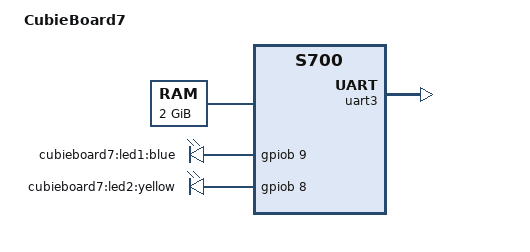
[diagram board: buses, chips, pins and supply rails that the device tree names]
/*
 * Copyright (c) 2017 Andreas Färber
 *
 * SPDX-License-Identifier: (GPL-2.0+ OR MIT)
 */

/dts-v1/;

#include <dt-bindings/gpio/gpio.h>

#include "s700.dtsi"

/ {
	compatible = "cubietech,cubieboard7", "actions,s700";
	model = "CubieBoard7";

	aliases {
		serial3 = &uart3;
	};

	chosen {
		stdout-path = "serial3:115200n8";
	};

	memory@0 {
		device_type = "memory";
		reg = <0x0 0x0 0x0 0x80000000>;
	};

	memory@1,e0000000 {
		device_type = "memory";
		reg = <0x1 0xe0000000 0x0 0x0>;
	};

	leds {
		compatible = "gpio-leds";

		led1 {
			label = "cubieboard7:led1:blue";
			gpios = <&gpiob 9 GPIO_ACTIVE_HIGH>;
			linux,default-trigger = "heartbeat";
		};

		led2 {
			label = "cubieboard7:led2:yellow";
			gpios = <&gpiob 8 GPIO_ACTIVE_HIGH>;
			linux,default-trigger = "heartbeat";
		};
	};

	uart3_clk: uart3-clk {
		compatible = "fixed-clock";
		clock-frequency = <921600>;
		#clock-cells = <0>;
	};
};

&timer {
	clocks = <&hosc>;
};

&uart3 {
	status = "okay";
	clocks = <&uart3_clk>;
};
